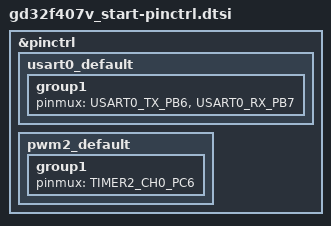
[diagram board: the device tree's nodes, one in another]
/*
 * Copyright (c) 2022, TOKITA Hiroshi <tokita.hiroshi@gmail.com>
 * SPDX-License-Identifier: Apache-2.0
 */

#include <dt-bindings/pinctrl/gd32f405z(e-g-k)xx-pinctrl.h>

&pinctrl {
	usart0_default: usart0_default {
		group1 {
			pinmux = <USART0_TX_PB6>, <USART0_RX_PB7>;
		};
	};

	pwm2_default: pwm2_default {
		group1 {
			pinmux = <TIMER2_CH0_PC6>;
		};
	};
};
